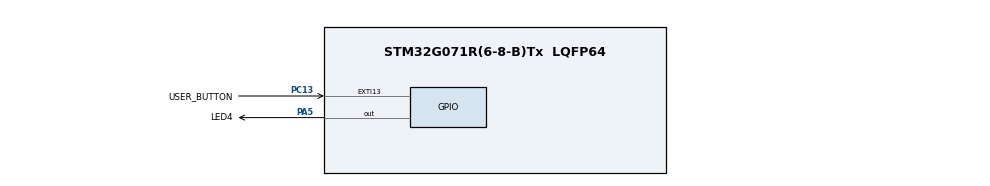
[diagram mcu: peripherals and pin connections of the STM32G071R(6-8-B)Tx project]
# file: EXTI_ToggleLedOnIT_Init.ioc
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Mcu.Family=STM32G0
Mcu.Name=STM32G071R(6-8-B)Tx
Mcu.Package=LQFP64
NVIC.EXTI4_15_IRQn=true\:0\:0\:false\:false\:true\:true\:true\:true
PA5.GPIO_Label=LED4
PA5.Signal=GPIO_Output
PC13.GPIO_Label=USER_BUTTON
PC13.GPIO_ModeDefaultEXTI=GPIO_MODE_IT_FALLING
PC13.GPIO_PuPd=GPIO_PULLUP
PC13.Signal=GPXTI13
ProjectManager.HeapSize=0x200
ProjectManager.StackSize=0x400
ProjectManager.TargetToolchain=EWARM V8.50
RCC.ADCFreq_Value=56000000
RCC.AHBFreq_Value=56000000
RCC.CodegenConfigPeriph=false
RCC.CortexFreq_Value=56000000
RCC.EXTERNAL_CLOCK_VALUE=48000
RCC.HCLKFreq_Value=56000000
RCC.HSE_VALUE=8000000
RCC.HSI_VALUE=16000000
RCC.LSE_VALUE=32768
RCC.PLLM=RCC_PLLM_DIV4
RCC.PLLN=70
RCC.PLLP=RCC_PLLP_DIV10
RCC.PLLQ=RCC_PLLQ_DIV5
RCC.PLLR=RCC_PLLR_DIV5
RCC.SYSCLKFreq_VALUE=56000000
RCC.SYSCLKSource=RCC_SYSCLKSOURCE_PLLCLK
RCC.VCOOutputFreq_Value=280000000
VP_SYS_VS_DBSignals.Mode=DisableDeadBatterySignals
board=custom

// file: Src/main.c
/* USER CODE BEGIN Header */
/**
  ******************************************************************************
  * @file    Examples_LL/EXTI/EXTI_ToggleLedOnIT_Init/Src/main.c
  * @author  MCD Application Team
  * @brief   This example describes how to configure the EXTI and use
  *          GPIOs using the STM32G0xx LL API to toggles the available
  *          users Leds on the board when User button is pressed.
  *          Peripheral initialization done using LL initialization function.
  ******************************************************************************
  * @attention
  *
  * Copyright (c) 2018-2020 STMicroelectronics.
  * All rights reserved.
  *
  * This software is licensed under terms that can be found in the LICENSE file
  * in the root directory of this software component.
  * If no LICENSE file comes with this software, it is provided AS-IS.
  *
  ******************************************************************************
  */
/* USER CODE END Header */
#include "main.h"

void SystemClock_Config(void);
static void MX_GPIO_Init(void);

int main(void)
{

  /* MCU Configuration--------------------------------------------------------*/

  /* Reset of all peripherals, Initializes the Flash interface and the Systick. */

  LL_APB2_GRP1_EnableClock(LL_APB2_GRP1_PERIPH_SYSCFG);
  LL_APB1_GRP1_EnableClock(LL_APB1_GRP1_PERIPH_PWR);

  /* System interrupt init*/

  /** Disable the internal Pull-Up in Dead Battery pins of UCPD peripheral
  */
  LL_SYSCFG_DisableDBATT(LL_SYSCFG_UCPD1_STROBE | LL_SYSCFG_UCPD2_STROBE);

  /* Configure the system clock */
  SystemClock_Config();

  /* Initialize all configured peripherals */
  MX_GPIO_Init();

  /* Infinite loop */
  while (1)
  {

  }
}

void SystemClock_Config(void)
{
  LL_FLASH_SetLatency(LL_FLASH_LATENCY_2);

  /* HSI configuration and activation */
  LL_RCC_HSI_Enable();
  while(LL_RCC_HSI_IsReady() != 1)
  {
  }

  /* Main PLL configuration and activation */
  LL_RCC_PLL_ConfigDomain_SYS(LL_RCC_PLLSOURCE_HSI, LL_RCC_PLLM_DIV_4, 70, LL_RCC_PLLR_DIV_5);
  LL_RCC_PLL_Enable();
  LL_RCC_PLL_EnableDomain_SYS();
  while(LL_RCC_PLL_IsReady() != 1)
  {
  }

  /* Set AHB prescaler*/
  LL_RCC_SetAHBPrescaler(LL_RCC_SYSCLK_DIV_1);

  /* Sysclk activation on the main PLL */
  LL_RCC_SetSysClkSource(LL_RCC_SYS_CLKSOURCE_PLL);
  while(LL_RCC_GetSysClkSource() != LL_RCC_SYS_CLKSOURCE_STATUS_PLL)
  {
  }

  /* Set APB1 prescaler*/
  LL_RCC_SetAPB1Prescaler(LL_RCC_APB1_DIV_1);
  LL_Init1msTick(56000000);
  /* Update CMSIS variable (which can be updated also through SystemCoreClockUpdate function) */
  LL_SetSystemCoreClock(56000000);
}

static void MX_GPIO_Init(void)
{
  LL_EXTI_InitTypeDef EXTI_InitStruct = {0};
  LL_GPIO_InitTypeDef GPIO_InitStruct = {0};

  /* GPIO Ports Clock Enable */
  LL_IOP_GRP1_EnableClock(LL_IOP_GRP1_PERIPH_GPIOC);
  LL_IOP_GRP1_EnableClock(LL_IOP_GRP1_PERIPH_GPIOA);

  /**/
  LL_GPIO_ResetOutputPin(LED4_GPIO_Port, LED4_Pin);

  /**/
  LL_EXTI_SetEXTISource(LL_EXTI_CONFIG_PORTC, LL_EXTI_CONFIG_LINE13);

  /**/
  EXTI_InitStruct.Line_0_31 = LL_EXTI_LINE_13;
  EXTI_InitStruct.LineCommand = ENABLE;
  EXTI_InitStruct.Mode = LL_EXTI_MODE_IT;
  EXTI_InitStruct.Trigger = LL_EXTI_TRIGGER_FALLING;
  LL_EXTI_Init(&EXTI_InitStruct);

  /**/
  LL_GPIO_SetPinPull(USER_BUTTON_GPIO_Port, USER_BUTTON_Pin, LL_GPIO_PULL_UP);

  /**/
  LL_GPIO_SetPinMode(USER_BUTTON_GPIO_Port, USER_BUTTON_Pin, LL_GPIO_MODE_INPUT);

  /**/
  GPIO_InitStruct.Pin = LED4_Pin;
  GPIO_InitStruct.Mode = LL_GPIO_MODE_OUTPUT;
  GPIO_InitStruct.Speed = LL_GPIO_SPEED_FREQ_LOW;
  GPIO_InitStruct.OutputType = LL_GPIO_OUTPUT_PUSHPULL;
  GPIO_InitStruct.Pull = LL_GPIO_PULL_NO;
  LL_GPIO_Init(LED4_GPIO_Port, &GPIO_InitStruct);

  /* EXTI interrupt init*/
  NVIC_SetPriority(EXTI4_15_IRQn, 0);
  NVIC_EnableIRQ(EXTI4_15_IRQn);

}

/* USER CODE BEGIN 4 */

/******************************************************************************/
/*   USER IRQ HANDLER TREATMENT                                               */
/******************************************************************************/
/**
  * @brief  Function to manage IRQ Handler
  * @param  None
  * @retval None
  */
void UserButton_Callback(void)
{
  LL_GPIO_TogglePin(LED4_GPIO_Port, LED4_Pin);
}

/* USER CODE END 4 */

void Error_Handler(void)
{
}

/************************ (C) COPYRIGHT STMicroelectronics *****END OF FILE****/
